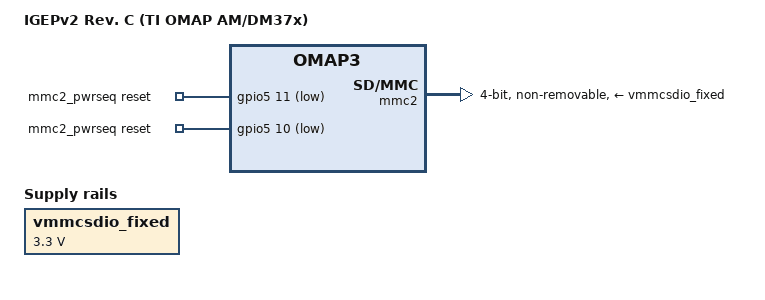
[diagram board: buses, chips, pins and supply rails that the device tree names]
#include "omap3-igep0020-common.dtsi"
/ {
	model = "IGEPv2 Rev. C (TI OMAP AM/DM37x)";
	compatible = "isee,omap3-igep0020", "ti,omap3630", "ti,omap3";
	vmmcsdio_fixed: fixedregulator-mmcsdio {
		compatible = "regulator-fixed";
		regulator-name = "vmmcsdio_fixed";
		regulator-min-microvolt = <3300000>;
		regulator-max-microvolt = <3300000>;
	};
	mmc2_pwrseq: mmc2_pwrseq {
		compatible = "mmc-pwrseq-simple";
		reset-gpios = <&gpio5 11 GPIO_ACTIVE_LOW>,	 
			      <&gpio5 10 GPIO_ACTIVE_LOW>;	 
	};
};
&omap3_pmx_core {
	lbee1usjyc_pins: lbee1usjyc-pins {
		pinctrl-single,pins = <
			OMAP3_CORE1_IOPAD(0x2166, PIN_OUTPUT | MUX_MODE4)	 
			OMAP3_CORE1_IOPAD(0x2168, PIN_OUTPUT | MUX_MODE4)	 
			OMAP3_CORE1_IOPAD(0x216a, PIN_OUTPUT | MUX_MODE4)	 
		>;
	};
};
&mmc2 {
	pinctrl-names = "default";
	pinctrl-0 = <&mmc2_pins &lbee1usjyc_pins>;
	vmmc-supply = <&vmmcsdio_fixed>;
	mmc-pwrseq = <&mmc2_pwrseq>;
	bus-width = <4>;
	non-removable;
};
